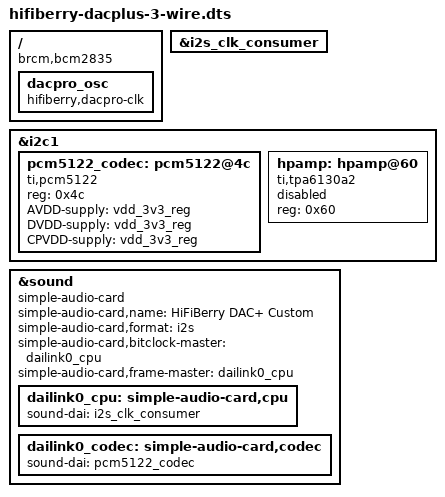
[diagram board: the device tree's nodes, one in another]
// Definitions for HiFiBerry DAC+
/dts-v1/;
/plugin/;

/ {
	compatible = "brcm,bcm2835";

	fragment@0 {
		target-path = "/";
		__overlay__ {
			dacpro_osc: dacpro_osc {
				compatible = "hifiberry,dacpro-clk";
				#clock-cells = <0>;
			};
		};
	};

	frag1: fragment@1 {
		target = <&i2s_clk_consumer>;
		__overlay__ {
			status = "okay";
		};
	};

	fragment@2 {
		target = <&i2c1>;
		__overlay__ {
			#address-cells = <1>;
			#size-cells = <0>;
			status = "okay";

			pcm5122_codec: pcm5122@4c {
				#sound-dai-cells = <0>;
				compatible = "ti,pcm5122";
				reg = <0x4c>;
				AVDD-supply = <&vdd_3v3_reg>;
				DVDD-supply = <&vdd_3v3_reg>;
				CPVDD-supply = <&vdd_3v3_reg>;
				status = "okay";
			};
			
			hpamp: hpamp@60 {
				compatible = "ti,tpa6130a2";
				reg = <0x60>;
				status = "disabled";
			};
		};
	};

	fragment@3 {
		target = <&sound>;
		hifiberry_dacplus: __overlay__ {
			compatible = "simple-audio-card";
			simple-audio-card,name = "HiFiBerry DAC+ Custom";
			simple-audio-card,format = "i2s";
			simple-audio-card,bitclock-master = <&dailink0_cpu>;
			simple-audio-card,frame-master = <&dailink0_cpu>;
			status = "okay";
			
			dailink0_cpu: simple-audio-card,cpu {
				sound-dai = <&i2s_clk_consumer>;
			};
			
			dailink0_codec: simple-audio-card,codec {
				sound-dai = <&pcm5122_codec>;
			};
		};
	};

	__overrides__ {
		slave = <&frag1>,"target:0=",<&i2s_clk_producer>,
			<&dailink0_cpu>,"sound-dai:0=",<&i2s_clk_producer>;
	};
};
